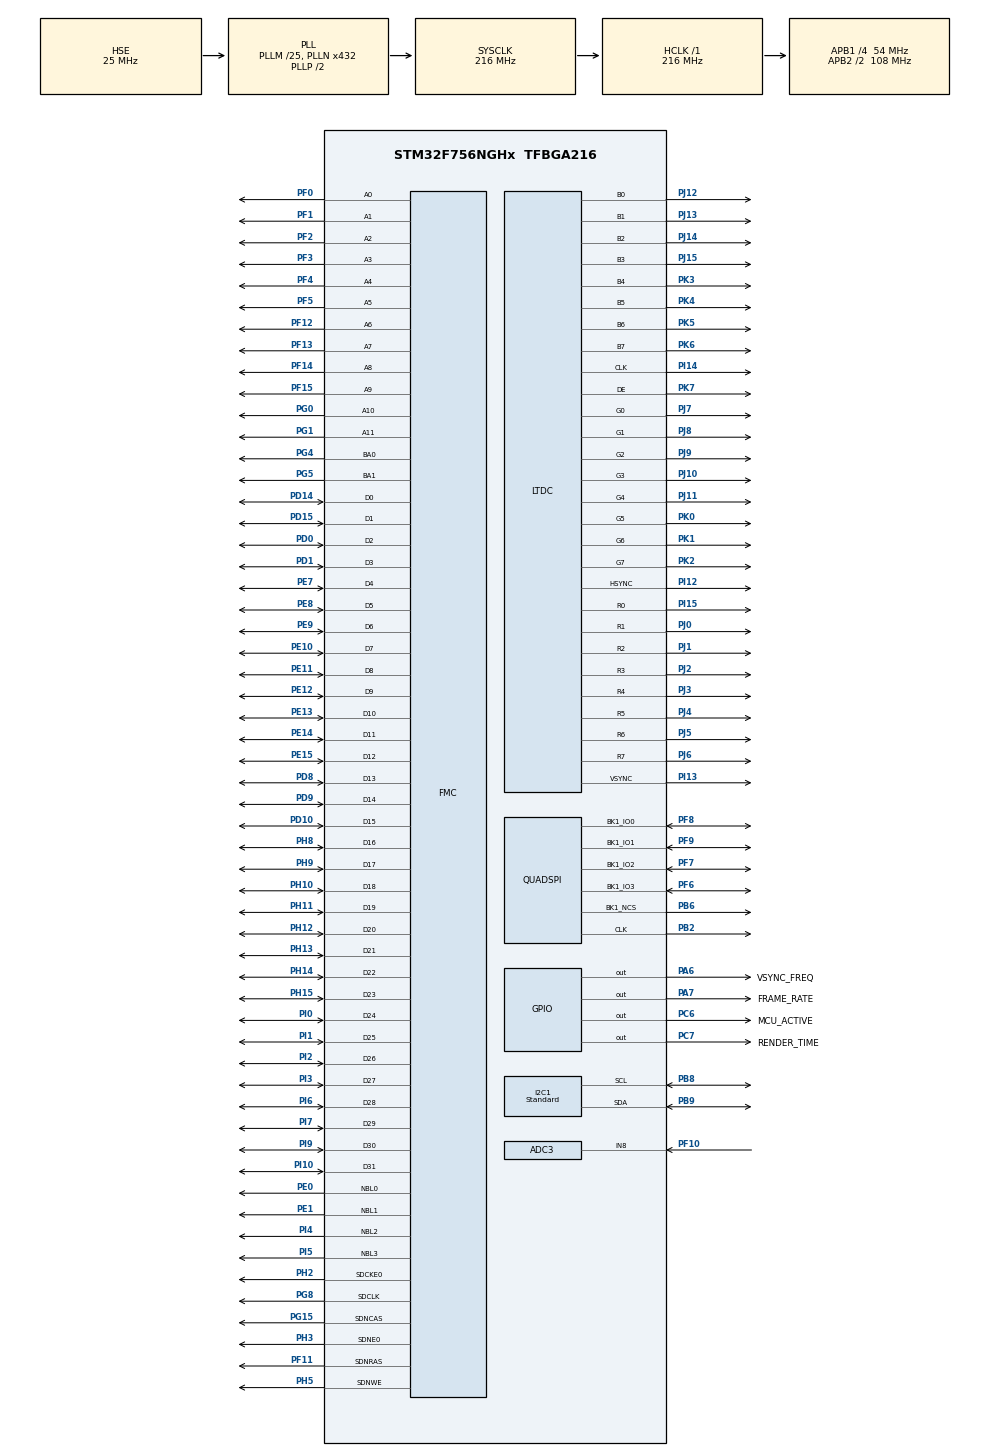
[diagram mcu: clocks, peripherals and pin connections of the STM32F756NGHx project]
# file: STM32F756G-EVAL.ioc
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ADC3.Channel-0\#ChannelRegularConversion=ADC_CHANNEL_8
ADC3.Channel-IN8=ADC_CHANNEL_8
ADC3.ClockPrescaler=ADC_CLOCK_SYNC_PCLK_DIV4
ADC3.ContinuousConvMode=DISABLE
ADC3.DMAContinuousRequests=DISABLE
ADC3.DataAlign=ADC_DATAALIGN_RIGHT
ADC3.DiscontinuousConvMode=DISABLE
ADC3.EOCSelection=ADC_EOC_SINGLE_CONV
ADC3.EnableAnalogWatchDog=false
ADC3.ExternalTrigConv=ADC_EXTERNALTRIGCONV_T1_CC1
ADC3.ExternalTrigConvEdge=ADC_EXTERNALTRIGCONVEDGE_RISING
ADC3.InjNumberOfConversion=0
ADC3.Mode=__NULL
ADC3.NbrOfConversion=1
ADC3.Rank-0\#ChannelRegularConversion=1
ADC3.Resolution=ADC_RESOLUTION_12B
ADC3.SamplingTime-0\#ChannelRegularConversion=ADC_SAMPLETIME_3CYCLES
ADC3.ScanConvMode=ADC_SCAN_DISABLE
CORTEX_M7.ART_ACCLERATOR_ENABLE=1
CORTEX_M7.AccessPermission-Cortex_Memory_Protection_Unit_Region0_Settings=MPU_REGION_NO_ACCESS
CORTEX_M7.AccessPermission-Cortex_Memory_Protection_Unit_Region1_Settings=MPU_REGION_FULL_ACCESS
CORTEX_M7.AccessPermission-Cortex_Memory_Protection_Unit_Region2_Settings=MPU_REGION_NO_ACCESS
CORTEX_M7.AccessPermission-Cortex_Memory_Protection_Unit_Region3_Settings=MPU_REGION_FULL_ACCESS
CORTEX_M7.BaseAddress-Cortex_Memory_Protection_Unit_Region0_Settings=0xC0000000
CORTEX_M7.BaseAddress-Cortex_Memory_Protection_Unit_Region1_Settings=0xC0000000
CORTEX_M7.BaseAddress-Cortex_Memory_Protection_Unit_Region2_Settings=0x90000000
CORTEX_M7.BaseAddress-Cortex_Memory_Protection_Unit_Region3_Settings=0x90000000
CORTEX_M7.CPU_DCache=Enabled
CORTEX_M7.CPU_ICache=Enabled
CORTEX_M7.DisableExec-Cortex_Memory_Protection_Unit_Region0_Settings=MPU_INSTRUCTION_ACCESS_DISABLE
CORTEX_M7.DisableExec-Cortex_Memory_Protection_Unit_Region1_Settings=MPU_INSTRUCTION_ACCESS_DISABLE
CORTEX_M7.DisableExec-Cortex_Memory_Protection_Unit_Region2_Settings=MPU_INSTRUCTION_ACCESS_DISABLE
CORTEX_M7.DisableExec-Cortex_Memory_Protection_Unit_Region3_Settings=MPU_INSTRUCTION_ACCESS_DISABLE
CORTEX_M7.Enable-Cortex_Memory_Protection_Unit_Region0_Settings=MPU_REGION_ENABLE
CORTEX_M7.Enable-Cortex_Memory_Protection_Unit_Region10_Settings=__NULL
CORTEX_M7.Enable-Cortex_Memory_Protection_Unit_Region11_Settings=__NULL
CORTEX_M7.Enable-Cortex_Memory_Protection_Unit_Region12_Settings=__NULL
CORTEX_M7.Enable-Cortex_Memory_Protection_Unit_Region13_Settings=__NULL
CORTEX_M7.Enable-Cortex_Memory_Protection_Unit_Region14_Settings=__NULL
CORTEX_M7.Enable-Cortex_Memory_Protection_Unit_Region15_Settings=__NULL
CORTEX_M7.Enable-Cortex_Memory_Protection_Unit_Region1_Settings=MPU_REGION_ENABLE
CORTEX_M7.Enable-Cortex_Memory_Protection_Unit_Region2_Settings=MPU_REGION_ENABLE
CORTEX_M7.Enable-Cortex_Memory_Protection_Unit_Region3_Settings=MPU_REGION_ENABLE
CORTEX_M7.Enable-Cortex_Memory_Protection_Unit_Region4_Settings=__NULL
CORTEX_M7.Enable-Cortex_Memory_Protection_Unit_Region5_Settings=__NULL
CORTEX_M7.Enable-Cortex_Memory_Protection_Unit_Region6_Settings=__NULL
CORTEX_M7.Enable-Cortex_Memory_Protection_Unit_Region7_Settings=__NULL
CORTEX_M7.Enable-Cortex_Memory_Protection_Unit_Region8_Settings=__NULL
CORTEX_M7.Enable-Cortex_Memory_Protection_Unit_Region9_Settings=__NULL
CORTEX_M7.FlashInterface=AXI_Enabled
CORTEX_M7.IsBufferable-Cortex_Memory_Protection_Unit_Region0_Settings=MPU_ACCESS_NOT_BUFFERABLE
CORTEX_M7.IsBufferable-Cortex_Memory_Protection_Unit_Region1_Settings=MPU_ACCESS_BUFFERABLE
CORTEX_M7.IsBufferable-Cortex_Memory_Protection_Unit_Region2_Settings=MPU_ACCESS_NOT_BUFFERABLE
CORTEX_M7.IsBufferable-Cortex_Memory_Protection_Unit_Region3_Settings=MPU_ACCESS_BUFFERABLE
CORTEX_M7.IsCacheable-Cortex_Memory_Protection_Unit_Region0_Settings=MPU_ACCESS_NOT_CACHEABLE
CORTEX_M7.IsCacheable-Cortex_Memory_Protection_Unit_Region1_Settings=MPU_ACCESS_CACHEABLE
CORTEX_M7.IsCacheable-Cortex_Memory_Protection_Unit_Region2_Settings=MPU_ACCESS_NOT_CACHEABLE
CORTEX_M7.IsCacheable-Cortex_Memory_Protection_Unit_Region3_Settings=MPU_ACCESS_CACHEABLE
CORTEX_M7.IsShareable-Cortex_Memory_Protection_Unit_Region0_Settings=MPU_ACCESS_NOT_SHAREABLE
CORTEX_M7.IsShareable-Cortex_Memory_Protection_Unit_Region1_Settings=MPU_ACCESS_NOT_SHAREABLE
CORTEX_M7.IsShareable-Cortex_Memory_Protection_Unit_Region2_Settings=MPU_ACCESS_NOT_SHAREABLE
CORTEX_M7.IsShareable-Cortex_Memory_Protection_Unit_Region3_Settings=MPU_ACCESS_NOT_SHAREABLE
CORTEX_M7.MPU_Control=MPU_PRIVILEGED_DEFAULT
CORTEX_M7.PREFETCH_ENABLE=1
CORTEX_M7.Size-Cortex_Memory_Protection_Unit_Region0_Settings=MPU_REGION_SIZE_512MB
CORTEX_M7.Size-Cortex_Memory_Protection_Unit_Region1_Settings=MPU_REGION_SIZE_8MB
CORTEX_M7.Size-Cortex_Memory_Protection_Unit_Region2_Settings=MPU_REGION_SIZE_512MB
CORTEX_M7.Size-Cortex_Memory_Protection_Unit_Region3_Settings=MPU_REGION_SIZE_64MB
CORTEX_M7.SubRegionDisable-Cortex_Memory_Protection_Unit_Region0_Settings=0x0
CORTEX_M7.SubRegionDisable-Cortex_Memory_Protection_Unit_Region1_Settings=0x0
CORTEX_M7.SubRegionDisable-Cortex_Memory_Protection_Unit_Region2_Settings=0x00
CORTEX_M7.SubRegionDisable-Cortex_Memory_Protection_Unit_Region3_Settings=0x0
CORTEX_M7.TypeExtField-Cortex_Memory_Protection_Unit_Region0_Settings=MPU_TEX_LEVEL0
CORTEX_M7.TypeExtField-Cortex_Memory_Protection_Unit_Region1_Settings=MPU_TEX_LEVEL0
CORTEX_M7.TypeExtField-Cortex_Memory_Protection_Unit_Region2_Settings=MPU_TEX_LEVEL0
CORTEX_M7.TypeExtField-Cortex_Memory_Protection_Unit_Region3_Settings=MPU_TEX_LEVEL0
CRC.DefaultInitValueUse=DEFAULT_INIT_VALUE_ENABLE
CRC.DefaultPolynomialUse=DEFAULT_POLYNOMIAL_ENABLE
CRC.InputDataFormat=CRC_INPUTDATA_FORMAT_WORDS
CRC.InputDataInversionMode=CRC_INPUTDATA_INVERSION_NONE
CRC.OutputDataInversionMode=CRC_OUTPUTDATA_INVERSION_DISABLE
DMA2D.ColorMode=DMA2D_OUTPUT_RGB565
DMA2D.Mode=DMA2D_R2M
DMA2D.OutputOffset=0
FMC.CASLatency1=FMC_SDRAM_CAS_LATENCY_3
FMC.ColumnBitsNumber1=FMC_SDRAM_COLUMN_BITS_NUM_9
FMC.ExitSelfRefreshDelay1=7
FMC.LoadToActiveDelay1=2
FMC.RCDDelay1=2
FMC.RPDelay1=2
FMC.ReadBurst1=FMC_SDRAM_RBURST_ENABLE
FMC.ReadPipeDelay1=FMC_SDRAM_RPIPE_DELAY_0
FMC.RowBitsNumber1=FMC_SDRAM_ROW_BITS_NUM_12
FMC.RowCycleDelay1=7
FMC.SDBank1=FMC_SDRAM_BANK1
FMC.SDClockPeriod1=FMC_SDRAM_CLOCK_PERIOD_2
FMC.SelfRefreshTime1=4
FMC.WriteProtection1=FMC_SDRAM_WRITE_PROTECTION_DISABLE
FMC.WriteRecoveryTime1=3
FREERTOS.HEAP_NUMBER=4
FREERTOS.INCLUDE_eTaskGetState=1
FREERTOS.INCLUDE_pcTaskGetTaskName=0
FREERTOS.INCLUDE_uxTaskGetStackHighWaterMark=1
FREERTOS.INCLUDE_uxTaskPriorityGet=1
FREERTOS.INCLUDE_vTaskCleanUpResources=0
FREERTOS.INCLUDE_vTaskDelay=1
FREERTOS.INCLUDE_vTaskDelayUntil=1
FREERTOS.INCLUDE_vTaskDelete=1
FREERTOS.INCLUDE_vTaskPrioritySet=1
FREERTOS.INCLUDE_vTaskSuspend=1
FREERTOS.INCLUDE_xEventGroupSetBitFromISR=0
FREERTOS.INCLUDE_xQueueGetMutexHolder=1
FREERTOS.INCLUDE_xSemaphoreGetMutexHolder=0
FREERTOS.INCLUDE_xTaskAbortDelay=0
FREERTOS.INCLUDE_xTaskGetCurrentTaskHandle=0
FREERTOS.INCLUDE_xTaskGetHandle=0
FREERTOS.INCLUDE_xTaskGetSchedulerState=1
FREERTOS.INCLUDE_xTaskResumeFromISR=1
FREERTOS.INCLUDE_xTimerPendFunctionCall=1
FREERTOS.Tasks01=defaultTask,24,128,StartDefaultTask,Default,NULL,Dynamic,NULL,NULL;TouchGFXTask,24,2048,TouchGFX_Task,As external,NULL,Dynamic,NULL,NULL
FREERTOS.configCHECK_FOR_STACK_OVERFLOW=0
FREERTOS.configENABLE_BACKWARD_COMPATIBILITY=1
FREERTOS.configGENERATE_RUN_TIME_STATS=0
FREERTOS.configIDLE_SHOULD_YIELD=1
FREERTOS.configLIBRARY_LOWEST_INTERRUPT_PRIORITY=15
FREERTOS.configLIBRARY_MAX_SYSCALL_INTERRUPT_PRIORITY=5
FREERTOS.configMAX_CO_ROUTINE_PRIORITIES=2
FREERTOS.configMAX_PRIORITIES=56
FREERTOS.configMAX_TASK_NAME_LEN=16
FREERTOS.configMINIMAL_STACK_SIZE=128
FREERTOS.configQUEUE_REGISTRY_SIZE=8
FREERTOS.configRECORD_STACK_HIGH_ADDRESS=0
FREERTOS.configTICK_RATE_HZ=1000
FREERTOS.configTIMER_QUEUE_LENGTH=10
FREERTOS.configTIMER_TASK_PRIORITY=2
FREERTOS.configTIMER_TASK_STACK_DEPTH=256
FREERTOS.configTOTAL_HEAP_SIZE=15360
FREERTOS.configUSE_APPLICATION_TASK_TAG=1
FREERTOS.configUSE_COUNTING_SEMAPHORES=1
FREERTOS.configUSE_CO_ROUTINES=0
FREERTOS.configUSE_DAEMON_TASK_STARTUP_HOOK=0
FREERTOS.configUSE_IDLE_HOOK=1
FREERTOS.configUSE_MALLOC_FAILED_HOOK=0
FREERTOS.configUSE_MUTEXES=1
FREERTOS.configUSE_PREEMPTION=1
FREERTOS.configUSE_RECURSIVE_MUTEXES=1
FREERTOS.configUSE_STATS_FORMATTING_FUNCTIONS=0
FREERTOS.configUSE_TASK_NOTIFICATIONS=1
FREERTOS.configUSE_TICKLESS_IDLE=0
FREERTOS.configUSE_TICK_HOOK=0
FREERTOS.configUSE_TRACE_FACILITY=1
I2C1.AddressingMode=I2C_ADDRESSINGMODE_7BIT
I2C1.Analog_Filter=I2C_ANALOGFILTER_ENABLE
I2C1.DualAddressMode=I2C_DUALADDRESS_DISABLE
I2C1.GeneralCallMode=I2C_GENERALCALL_DISABLE
I2C1.I2C_Coeff_DF=0
I2C1.I2C_Fall_Time=0
I2C1.I2C_Rise_Time=0
I2C1.I2C_Speed_Mode=I2C_Standard
I2C1.NoStretchMode=I2C_NOSTRETCH_DISABLE
I2C1.OwnAddress=0
I2C1.Speed=100
I2C1.Timing=0x20404768
LTDC.ActiveH=480
LTDC.ActiveW=640
LTDC.Alpha0_L0=0
LTDC.Alpha_L0=255
LTDC.BlendingFactor1_L0=LTDC_BLENDING_FACTOR1_CA
LTDC.BlendingFactor2_L0=LTDC_BLENDING_FACTOR2_CA
LTDC.Blue=0
LTDC.Blue_L0=0
LTDC.DEPolarity=LTDC_DEPOLARITY_AL
LTDC.FBStartAdress_L0=0xc0000000
LTDC.Green=0
LTDC.Green_L0=0
LTDC.HBP=114
LTDC.HFP=16
LTDC.HSPolarity=LTDC_HSPOLARITY_AL
LTDC.HSync=30
LTDC.ImageHeight_L0=480
LTDC.ImageWidth_L0=640
LTDC.Layers=0
LTDC.PCPolarity=LTDC_PCPOLARITY_IPC
LTDC.PixelFormat_L0=LTDC_PIXEL_FORMAT_RGB565
LTDC.Red=0
LTDC.Red_L0=0
LTDC.VBP=32
LTDC.VFP=10
LTDC.VSPolarity=LTDC_VSPOLARITY_AL
LTDC.VSync=3
LTDC.WindowX0_L0=0
LTDC.WindowX1_L0=640
LTDC.WindowY0_L0=0
LTDC.WindowY1_L0=480
Mcu.Family=STM32F7
Mcu.Name=STM32F756NGHx
Mcu.Package=TFBGA216
NVIC.DMA2D_IRQn=true\:5\:0\:true\:false\:true\:false\:true\:true\:true
NVIC.I2C1_EV_IRQn=true\:5\:0\:false\:false\:true\:false\:true\:true\:true
NVIC.LTDC_IRQn=true\:5\:0\:true\:false\:true\:false\:true\:true\:true
NVIC.PriorityGroup=NVIC_PRIORITYGROUP_4
NVIC.TIM6_DAC_IRQn=true\:0\:0\:false\:false\:true\:false\:false\:true\:true
NVIC.TimeBase=TIM6_DAC_IRQn
NVIC.TimeBaseIP=TIM6
PA13.Mode=Serial_Wire
PA13.Signal=SYS_JTMS-SWDIO
PA14.Mode=Serial_Wire
PA14.Signal=SYS_JTCK-SWCLK
PA6.GPIO_Label=VSYNC_FREQ
PA6.GPIO_Speed=GPIO_SPEED_FREQ_VERY_HIGH
PA6.Signal=GPIO_Output
PA7.GPIO_Label=FRAME_RATE
PA7.GPIO_Speed=GPIO_SPEED_FREQ_VERY_HIGH
PA7.Signal=GPIO_Output
PB2.Mode=Single Bank 1
PB2.Signal=QUADSPI_CLK
PB6.GPIO_PuPd=GPIO_PULLUP
PB6.Mode=Single Bank 1
PB6.Signal=QUADSPI_BK1_NCS
PB8.GPIO_Pu=GPIO_NOPULL
PB8.Mode=I2C
PB8.Signal=I2C1_SCL
PB9.GPIO_Pu=GPIO_NOPULL
PB9.Mode=I2C
PB9.Signal=I2C1_SDA
PC6.GPIO_Label=MCU_ACTIVE
PC6.GPIO_Speed=GPIO_SPEED_FREQ_VERY_HIGH
PC6.Signal=GPIO_Output
PC7.GPIO_Label=RENDER_TIME
PC7.GPIO_Speed=GPIO_SPEED_FREQ_VERY_HIGH
PC7.Signal=GPIO_Output
PD0.GPIO_PuPd=GPIO_PULLUP
PD0.Signal=FMC_D2_DA2
PD1.GPIO_PuPd=GPIO_PULLUP
PD1.Signal=FMC_D3_DA3
PD10.GPIO_PuPd=GPIO_PULLUP
PD10.Signal=FMC_D15_DA15
PD14.GPIO_PuPd=GPIO_PULLUP
PD14.Signal=FMC_D0_DA0
PD15.GPIO_PuPd=GPIO_PULLUP
PD15.Signal=FMC_D1_DA1
PD8.GPIO_PuPd=GPIO_PULLUP
PD8.Signal=FMC_D13_DA13
PD9.GPIO_PuPd=GPIO_PULLUP
PD9.Signal=FMC_D14_DA14
PE0.GPIO_PuPd=GPIO_PULLUP
PE0.Signal=FMC_NBL0
PE1.GPIO_PuPd=GPIO_PULLUP
PE1.Signal=FMC_NBL1
PE10.GPIO_PuPd=GPIO_PULLUP
PE10.Signal=FMC_D7_DA7
PE11.GPIO_PuPd=GPIO_PULLUP
PE11.Signal=FMC_D8_DA8
PE12.GPIO_PuPd=GPIO_PULLUP
PE12.Signal=FMC_D9_DA9
PE13.GPIO_PuPd=GPIO_PULLUP
PE13.Signal=FMC_D10_DA10
PE14.GPIO_PuPd=GPIO_PULLUP
PE14.Signal=FMC_D11_DA11
PE15.GPIO_PuPd=GPIO_PULLUP
PE15.Signal=FMC_D12_DA12
PE7.GPIO_PuPd=GPIO_PULLUP
PE7.Signal=FMC_D4_DA4
PE8.GPIO_PuPd=GPIO_PULLUP
PE8.Signal=FMC_D5_DA5
PE9.GPIO_PuPd=GPIO_PULLUP
PE9.Signal=FMC_D6_DA6
PF0.GPIO_PuPd=GPIO_PULLUP
PF0.Signal=FMC_A0
PF1.GPIO_PuPd=GPIO_PULLUP
PF1.Signal=FMC_A1
PF10.Mode=IN8
PF10.Signal=ADC3_IN8
PF11.GPIO_PuPd=GPIO_PULLUP
PF11.Signal=FMC_SDNRAS
PF12.GPIO_PuPd=GPIO_PULLUP
PF12.Signal=FMC_A6
PF13.GPIO_PuPd=GPIO_PULLUP
PF13.Signal=FMC_A7
PF14.GPIO_PuPd=GPIO_PULLUP
PF14.Signal=FMC_A8
PF15.GPIO_PuPd=GPIO_PULLUP
PF15.Signal=FMC_A9
PF2.GPIO_PuPd=GPIO_PULLUP
PF2.Signal=FMC_A2
PF3.GPIO_PuPd=GPIO_PULLUP
PF3.Signal=FMC_A3
PF4.GPIO_PuPd=GPIO_PULLUP
PF4.Signal=FMC_A4
PF5.GPIO_PuPd=GPIO_PULLUP
PF5.Signal=FMC_A5
PF6.Mode=Single Bank 1
PF6.Signal=QUADSPI_BK1_IO3
PF7.Mode=Single Bank 1
PF7.Signal=QUADSPI_BK1_IO2
PF8.Mode=Single Bank 1
PF8.Signal=QUADSPI_BK1_IO0
PF9.Mode=Single Bank 1
PF9.Signal=QUADSPI_BK1_IO1
PG0.GPIO_PuPd=GPIO_PULLUP
PG0.Signal=FMC_A10
PG1.GPIO_PuPd=GPIO_PULLUP
PG1.Signal=FMC_A11
PG15.GPIO_PuPd=GPIO_PULLUP
PG15.Signal=FMC_SDNCAS
PG4.GPIO_PuPd=GPIO_PULLUP
PG4.Signal=FMC_A14_BA0
PG5.GPIO_PuPd=GPIO_PULLUP
PG5.Signal=FMC_A15_BA1
PG8.GPIO_PuPd=GPIO_PULLUP
PG8.Signal=FMC_SDCLK
PH0/OSC_IN.Mode=HSE-External-Oscillator
PH0/OSC_IN.Signal=RCC_OSC_IN
PH1/OSC_OUT.Mode=HSE-External-Oscillator
PH1/OSC_OUT.Signal=RCC_OSC_OUT
PH10.GPIO_PuPd=GPIO_PULLUP
PH10.Signal=FMC_D18
PH11.GPIO_PuPd=GPIO_PULLUP
PH11.Signal=FMC_D19
PH12.GPIO_PuPd=GPIO_PULLUP
PH12.Signal=FMC_D20
PH13.GPIO_PuPd=GPIO_PULLUP
PH13.Signal=FMC_D21
PH14.GPIO_PuPd=GPIO_PULLUP
PH14.Signal=FMC_D22
PH15.GPIO_PuPd=GPIO_PULLUP
PH15.Signal=FMC_D23
PH2.GPIO_PuPd=GPIO_PULLUP
PH2.Mode=SdramChipSelect1_1
PH2.Signal=FMC_SDCKE0
PH3.GPIO_PuPd=GPIO_PULLUP
PH3.Mode=SdramChipSelect1_1
PH3.Signal=FMC_SDNE0
PH5.GPIO_PuPd=GPIO_PULLUP
PH5.Signal=FMC_SDNWE
PH8.GPIO_PuPd=GPIO_PULLUP
PH8.Signal=FMC_D16
PH9.GPIO_PuPd=GPIO_PULLUP
PH9.Signal=FMC_D17
PI0.GPIO_PuPd=GPIO_PULLUP
PI0.Signal=FMC_D24
PI1.GPIO_PuPd=GPIO_PULLUP
PI1.Signal=FMC_D25
PI10.GPIO_PuPd=GPIO_PULLUP
PI10.Signal=FMC_D31
PI12.GPIO_Speed=GPIO_SPEED_FREQ_HIGH
PI12.Mode=RGB888
PI12.Signal=LTDC_HSYNC
PI13.GPIO_Speed=GPIO_SPEED_FREQ_HIGH
PI13.Mode=RGB888
PI13.Signal=LTDC_VSYNC
PI14.GPIO_Speed=GPIO_SPEED_FREQ_HIGH
PI14.Mode=RGB888
PI14.Signal=LTDC_CLK
PI15.GPIO_Speed=GPIO_SPEED_FREQ_HIGH
PI15.Mode=RGB888
PI15.Signal=LTDC_R0
PI2.GPIO_PuPd=GPIO_PULLUP
PI2.Signal=FMC_D26
PI3.GPIO_PuPd=GPIO_PULLUP
PI3.Signal=FMC_D27
PI4.GPIO_PuPd=GPIO_PULLUP
PI4.Signal=FMC_NBL2
PI5.GPIO_PuPd=GPIO_PULLUP
PI5.Signal=FMC_NBL3
PI6.GPIO_PuPd=GPIO_PULLUP
PI6.Signal=FMC_D28
PI7.GPIO_PuPd=GPIO_PULLUP
PI7.Signal=FMC_D29
PI9.GPIO_PuPd=GPIO_PULLUP
PI9.Signal=FMC_D30
PJ0.GPIO_Speed=GPIO_SPEED_FREQ_HIGH
PJ0.Mode=RGB888
PJ0.Signal=LTDC_R1
PJ1.GPIO_Speed=GPIO_SPEED_FREQ_HIGH
PJ1.Mode=RGB888
PJ1.Signal=LTDC_R2
PJ10.GPIO_Speed=GPIO_SPEED_FREQ_HIGH
PJ10.Mode=RGB888
PJ10.Signal=LTDC_G3
PJ11.GPIO_Speed=GPIO_SPEED_FREQ_HIGH
PJ11.Mode=RGB888
PJ11.Signal=LTDC_G4
PJ12.GPIO_Speed=GPIO_SPEED_FREQ_HIGH
PJ12.Mode=RGB888
PJ12.Signal=LTDC_B0
PJ13.GPIO_Speed=GPIO_SPEED_FREQ_HIGH
PJ13.Mode=RGB888
PJ13.Signal=LTDC_B1
PJ14.GPIO_Speed=GPIO_SPEED_FREQ_HIGH
PJ14.Mode=RGB888
PJ14.Signal=LTDC_B2
PJ15.GPIO_Speed=GPIO_SPEED_FREQ_HIGH
PJ15.Mode=RGB888
PJ15.Signal=LTDC_B3
PJ2.GPIO_Speed=GPIO_SPEED_FREQ_HIGH
PJ2.Mode=RGB888
PJ2.Signal=LTDC_R3
PJ3.GPIO_Speed=GPIO_SPEED_FREQ_HIGH
PJ3.Mode=RGB888
PJ3.Signal=LTDC_R4
PJ4.GPIO_Speed=GPIO_SPEED_FREQ_HIGH
PJ4.Mode=RGB888
PJ4.Signal=LTDC_R5
PJ5.GPIO_Speed=GPIO_SPEED_FREQ_HIGH
PJ5.Mode=RGB888
PJ5.Signal=LTDC_R6
PJ6.GPIO_Speed=GPIO_SPEED_FREQ_HIGH
PJ6.Mode=RGB888
PJ6.Signal=LTDC_R7
PJ7.GPIO_Speed=GPIO_SPEED_FREQ_HIGH
PJ7.Mode=RGB888
PJ7.Signal=LTDC_G0
PJ8.GPIO_Speed=GPIO_SPEED_FREQ_HIGH
PJ8.Mode=RGB888
PJ8.Signal=LTDC_G1
PJ9.GPIO_Speed=GPIO_SPEED_FREQ_HIGH
PJ9.Mode=RGB888
PJ9.Signal=LTDC_G2
PK0.GPIO_Speed=GPIO_SPEED_FREQ_HIGH
PK0.Mode=RGB888
PK0.Signal=LTDC_G5
PK1.GPIO_Speed=GPIO_SPEED_FREQ_HIGH
PK1.Mode=RGB888
PK1.Signal=LTDC_G6
PK2.GPIO_Speed=GPIO_SPEED_FREQ_HIGH
PK2.Mode=RGB888
PK2.Signal=LTDC_G7
PK3.GPIO_Speed=GPIO_SPEED_FREQ_HIGH
PK3.Mode=RGB888
PK3.Signal=LTDC_B4
PK4.GPIO_Speed=GPIO_SPEED_FREQ_HIGH
PK4.Mode=RGB888
PK4.Signal=LTDC_B5
PK5.GPIO_Speed=GPIO_SPEED_FREQ_HIGH
PK5.Mode=RGB888
PK5.Signal=LTDC_B6
PK6.GPIO_Speed=GPIO_SPEED_FREQ_HIGH
PK6.Mode=RGB888
PK6.Signal=LTDC_B7
PK7.GPIO_Speed=GPIO_SPEED_FREQ_HIGH
PK7.Mode=RGB888
PK7.Signal=LTDC_DE
ProjectManager.HeapSize=0x1000
ProjectManager.StackSize=0x1000
ProjectManager.TargetToolchain=STM32CubeIDE
QUADSPI.ChipSelectHighTime=QSPI_CS_HIGH_TIME_6_CYCLE
QUADSPI.ClockMode=QSPI_CLOCK_MODE_0
QUADSPI.ClockPrescaler=1
QUADSPI.DualFlash=QSPI_DUALFLASH_DISABLE
QUADSPI.FifoThreshold=4
QUADSPI.FlashID=QSPI_FLASH_ID_1
QUADSPI.FlashSize=25
QUADSPI.SampleShifting=QSPI_SAMPLE_SHIFTING_HALFCYCLE
RCC.AHBFreq_Value=216000000
RCC.APB1CLKDivider=RCC_HCLK_DIV4
RCC.APB1Freq_Value=54000000
RCC.APB1TimFreq_Value=108000000
RCC.APB2CLKDivider=RCC_HCLK_DIV2
RCC.APB2Freq_Value=108000000
RCC.APB2TimFreq_Value=216000000
RCC.CortexFreq_Value=216000000
RCC.FLatency=FLASH_LATENCY_7
RCC.HCLKFreq_Value=216000000
RCC.HSE_VALUE=25000000
RCC.HSI_VALUE=16000000
RCC.LSE_VALUE=32768
RCC.PLLM=25
RCC.PLLN=432
RCC.PLLSAIN=100
RCC.PLLSourceVirtual=RCC_PLLSOURCE_HSE
RCC.PWREXT_OverDrive=PWREXT_OverDrive_ACTIVATED
RCC.PWR_Regulator_Voltage_Scale=PWR_REGULATOR_VOLTAGE_SCALE1
RCC.SYSCLKFreq_VALUE=216000000
RCC.SYSCLKSource=RCC_SYSCLKSOURCE_PLLCLK
RCC.USBFreq_Value=216000000
RCC.VCOOutputFreq_Value=432000000
SH.FMC_A0.0=FMC_A0,12b-sda1
SH.FMC_A1.0=FMC_A1,12b-sda1
SH.FMC_A10.0=FMC_A10,12b-sda1
SH.FMC_A11.0=FMC_A11,12b-sda1
SH.FMC_A14_BA0.0=FMC_BA0,FourSdramBanks1
SH.FMC_A15_BA1.0=FMC_BA1,FourSdramBanks1
SH.FMC_A2.0=FMC_A2,12b-sda1
SH.FMC_A3.0=FMC_A3,12b-sda1
SH.FMC_A4.0=FMC_A4,12b-sda1
SH.FMC_A5.0=FMC_A5,12b-sda1
SH.FMC_A6.0=FMC_A6,12b-sda1
SH.FMC_A7.0=FMC_A7,12b-sda1
SH.FMC_A8.0=FMC_A8,12b-sda1
SH.FMC_A9.0=FMC_A9,12b-sda1
SH.FMC_D0_DA0.0=FMC_D0,sd-32b-d1
SH.FMC_D10_DA10.0=FMC_D10,sd-32b-d1
SH.FMC_D11_DA11.0=FMC_D11,sd-32b-d1
SH.FMC_D12_DA12.0=FMC_D12,sd-32b-d1
SH.FMC_D13_DA13.0=FMC_D13,sd-32b-d1
SH.FMC_D14_DA14.0=FMC_D14,sd-32b-d1
SH.FMC_D15_DA15.0=FMC_D15,sd-32b-d1
SH.FMC_D16.0=FMC_D16,sd-32b-d1
SH.FMC_D17.0=FMC_D17,sd-32b-d1
SH.FMC_D18.0=FMC_D18,sd-32b-d1
SH.FMC_D19.0=FMC_D19,sd-32b-d1
SH.FMC_D1_DA1.0=FMC_D1,sd-32b-d1
SH.FMC_D20.0=FMC_D20,sd-32b-d1
SH.FMC_D21.0=FMC_D21,sd-32b-d1
SH.FMC_D22.0=FMC_D22,sd-32b-d1
SH.FMC_D23.0=FMC_D23,sd-32b-d1
SH.FMC_D24.0=FMC_D24,sd-32b-d1
SH.FMC_D25.0=FMC_D25,sd-32b-d1
SH.FMC_D26.0=FMC_D26,sd-32b-d1
SH.FMC_D27.0=FMC_D27,sd-32b-d1
SH.FMC_D28.0=FMC_D28,sd-32b-d1
SH.FMC_D29.0=FMC_D29,sd-32b-d1
SH.FMC_D2_DA2.0=FMC_D2,sd-32b-d1
SH.FMC_D30.0=FMC_D30,sd-32b-d1
SH.FMC_D31.0=FMC_D31,sd-32b-d1
SH.FMC_D3_DA3.0=FMC_D3,sd-32b-d1
SH.FMC_D4_DA4.0=FMC_D4,sd-32b-d1
SH.FMC_D5_DA5.0=FMC_D5,sd-32b-d1
SH.FMC_D6_DA6.0=FMC_D6,sd-32b-d1
SH.FMC_D7_DA7.0=FMC_D7,sd-32b-d1
SH.FMC_D8_DA8.0=FMC_D8,sd-32b-d1
SH.FMC_D9_DA9.0=FMC_D9,sd-32b-d1
SH.FMC_NBL0.0=FMC_NBL0,Sd4ByteEnable1
SH.FMC_NBL1.0=FMC_NBL1,Sd4ByteEnable1
SH.FMC_NBL2.0=FMC_NBL2,Sd4ByteEnable1
SH.FMC_NBL3.0=FMC_NBL3,Sd4ByteEnable1
SH.FMC_SDCLK.0=FMC_SDCLK,12b-sda1
SH.FMC_SDNCAS.0=FMC_SDNCAS,12b-sda1
SH.FMC_SDNRAS.0=FMC_SDNRAS,12b-sda1
SH.FMC_SDNWE.0=FMC_SDNWE,12b-sda1
STMicroelectronics.X-CUBE-TOUCHGFX.4.22.0.ApplicationCcGraphicsJjApplication=TouchGFXOoGenerator
STMicroelectronics.X-CUBE-TOUCHGFX.4.22.0.tgfx_address1=0xC0000000
STMicroelectronics.X-CUBE-TOUCHGFX.4.22.0.tgfx_address2=0xC0096000
STMicroelectronics.X-CUBE-TOUCHGFX.4.22.0.tgfx_buffering_strategy=Double
STMicroelectronics.X-CUBE-TOUCHGFX.4.22.0.tgfx_display_interface=disp_ltdc
STMicroelectronics.X-CUBE-TOUCHGFX.4.22.0.tgfx_hardware_accelerator=dma_2d
STMicroelectronics.X-CUBE-TOUCHGFX.4.22.0.tgfx_location=By Address
STMicroelectronics.X-CUBE-TOUCHGFX.4.22.0.tgfx_vector_rendering=Enabled
STMicroelectronics.X-CUBE-TOUCHGFX.4.22.0.tgfx_vsync=vsync_ltdc
VP_CRC_VS_CRC.Mode=CRC_Activate
VP_DMA2D_VS_DMA2D.Mode=DMA2D_Activate
VP_FREERTOS_VS_CMSIS_V2.Mode=CMSIS_V2
VP_STMicroelectronics.X-CUBE-TOUCHGFX_VS_GraphicsJjApplication_4.22.0.Mode=GraphicsJjApplication
VP_SYS_VS_tim6.Mode=TIM6
board=custom

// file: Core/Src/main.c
/* USER CODE BEGIN Header */
/**
  ******************************************************************************
  * @file           : main.c
  * @brief          : Main program body
  ******************************************************************************
  * @attention
  *
  * <h2><center>&copy; Copyright (c) 2020 STMicroelectronics.
  * All rights reserved.</center></h2>
  *
  * This software component is licensed by ST under BSD 3-Clause license,
  * the "License"; You may not use this file except in compliance with the
  * License. You may obtain a copy of the License at:
  *                        opensource.org/licenses/BSD-3-Clause
  *
  ******************************************************************************
  */
/* USER CODE END Header */
#include "main.h"
#include "cmsis_os.h"
#include "app_touchgfx.h"

/* USER CODE BEGIN Includes */
#include "../n25q512a/n25q512a.h"
#include "../ft5336/ft5336.h"

/* USER CODE END Includes */

/* USER CODE BEGIN PD */
/* QSPI Error codes */
#define QSPI_OK            ((uint8_t)0x00)
#define QSPI_ERROR         ((uint8_t)0x01)
#define QSPI_BUSY          ((uint8_t)0x02)
#define QSPI_NOT_SUPPORTED ((uint8_t)0x04)
#define QSPI_SUSPENDED     ((uint8_t)0x08)
// SDRAM
#define REFRESH_COUNT                    ((uint32_t)0x0603)   /* SDRAM refresh counter (100Mhz SD clock) */
#define SDRAM_TIMEOUT                    ((uint32_t)0xFFFF)
//  FMC SDRAM Mode definition register defines
#define SDRAM_MODEREG_BURST_LENGTH_1             ((uint16_t)0x0000)
#define SDRAM_MODEREG_BURST_LENGTH_2             ((uint16_t)0x0001)
#define SDRAM_MODEREG_BURST_LENGTH_4             ((uint16_t)0x0002)
#define SDRAM_MODEREG_BURST_LENGTH_8             ((uint16_t)0x0004)
#define SDRAM_MODEREG_BURST_TYPE_SEQUENTIAL      ((uint16_t)0x0000)
#define SDRAM_MODEREG_BURST_TYPE_INTERLEAVED     ((uint16_t)0x0008)
#define SDRAM_MODEREG_CAS_LATENCY_2              ((uint16_t)0x0020)
#define SDRAM_MODEREG_CAS_LATENCY_3              ((uint16_t)0x0030)
#define SDRAM_MODEREG_OPERATING_MODE_STANDARD    ((uint16_t)0x0000)
#define SDRAM_MODEREG_WRITEBURST_MODE_PROGRAMMED ((uint16_t)0x0000)
#define SDRAM_MODEREG_WRITEBURST_MODE_SINGLE     ((uint16_t)0x0200)

/* USER CODE END PD */

ADC_HandleTypeDef hadc3;

CRC_HandleTypeDef hcrc;

DMA2D_HandleTypeDef hdma2d;

I2C_HandleTypeDef hi2c1;

LTDC_HandleTypeDef hltdc;

QSPI_HandleTypeDef hqspi;

SDRAM_HandleTypeDef hsdram1;

/* Definitions for defaultTask */
osThreadId_t defaultTaskHandle;
const osThreadAttr_t defaultTask_attributes = {
  .name = "defaultTask",
  .stack_size = 128 * 4,
  .priority = (osPriority_t) osPriorityNormal,
};
/* Definitions for TouchGFXTask */
osThreadId_t TouchGFXTaskHandle;
const osThreadAttr_t TouchGFXTask_attributes = {
  .name = "TouchGFXTask",
  .stack_size = 2048 * 4,
  .priority = (osPriority_t) osPriorityNormal,
};

void SystemClock_Config(void);
static void MPU_Initialize(void);
static void MPU_Config(void);
static void MX_GPIO_Init(void);
static void MX_QUADSPI_Init(void);
static void MX_FMC_Init(void);
static void MX_LTDC_Init(void);
static void MX_CRC_Init(void);
static void MX_DMA2D_Init(void);
static void MX_ADC3_Init(void);
static void MX_I2C1_Init(void);
void StartDefaultTask(void *argument);
extern void TouchGFX_Task(void *argument);

/* USER CODE BEGIN PFP */
static uint8_t QSPI_ResetMemory          (QSPI_HandleTypeDef *hqspi);
static uint8_t QSPI_EnterFourBytesAddress(QSPI_HandleTypeDef *hqspi);
static uint8_t QSPI_DummyCyclesCfg       (QSPI_HandleTypeDef *hqspi);
static uint8_t QSPI_WriteEnable          (QSPI_HandleTypeDef *hqspi);
static uint8_t QSPI_AutoPollingMemReady(QSPI_HandleTypeDef *hqspi, uint32_t Timeout);
static uint8_t QSPI_EnableMemoryMappedMode(void);

static FMC_SDRAM_CommandTypeDef Command;
void    BSP_SDRAM_Initialization_sequence(uint32_t RefreshCount);

/* USER CODE END PFP */

int main(void)
{

  /* Enable I-Cache---------------------------------------------------------*/
  SCB_EnableICache();

  /* Enable D-Cache---------------------------------------------------------*/
  SCB_EnableDCache();

  /* MCU Configuration--------------------------------------------------------*/

  /* Reset of all peripherals, Initializes the Flash interface and the Systick. */
  HAL_Init();

  /* MPU Configuration--------------------------------------------------------*/
  MPU_Config();

  /* Configure the system clock */
  SystemClock_Config();

  /* Initialize all configured peripherals */
  MX_GPIO_Init();
  MX_QUADSPI_Init();
  MX_FMC_Init();
  MX_LTDC_Init();
  MX_CRC_Init();
  MX_DMA2D_Init();
  MX_ADC3_Init();
  MX_I2C1_Init();
  MX_TouchGFX_Init();
  /* Call PreOsInit function */
  MX_TouchGFX_PreOSInit();

  /* Init scheduler */
  osKernelInitialize();

  /* Create the thread(s) */
  /* creation of defaultTask */
  defaultTaskHandle = osThreadNew(StartDefaultTask, NULL, &defaultTask_attributes);

  /* creation of TouchGFXTask */
  TouchGFXTaskHandle = osThreadNew(TouchGFX_Task, NULL, &TouchGFXTask_attributes);

  /* Start scheduler */
  osKernelStart();

  /* We should never get here as control is now taken by the scheduler */
  /* Infinite loop */
  while (1)
  {

  }
}

void SystemClock_Config(void)
{
  RCC_OscInitTypeDef RCC_OscInitStruct = {0};
  RCC_ClkInitTypeDef RCC_ClkInitStruct = {0};

  /** Configure the main internal regulator output voltage
  */
  __HAL_RCC_PWR_CLK_ENABLE();
  __HAL_PWR_VOLTAGESCALING_CONFIG(PWR_REGULATOR_VOLTAGE_SCALE1);

  /** Initializes the RCC Oscillators according to the specified parameters
  * in the RCC_OscInitTypeDef structure.
  */
  RCC_OscInitStruct.OscillatorType = RCC_OSCILLATORTYPE_HSE;
  RCC_OscInitStruct.HSEState = RCC_HSE_ON;
  RCC_OscInitStruct.PLL.PLLState = RCC_PLL_ON;
  RCC_OscInitStruct.PLL.PLLSource = RCC_PLLSOURCE_HSE;
  RCC_OscInitStruct.PLL.PLLM = 25;
  RCC_OscInitStruct.PLL.PLLN = 432;
  RCC_OscInitStruct.PLL.PLLP = RCC_PLLP_DIV2;
  RCC_OscInitStruct.PLL.PLLQ = 2;
  if (HAL_RCC_OscConfig(&RCC_OscInitStruct) != HAL_OK)
  {
    Error_Handler();
  }

  /** Activate the Over-Drive mode
  */
  if (HAL_PWREx_EnableOverDrive() != HAL_OK)
  {
    Error_Handler();
  }

  /** Initializes the CPU, AHB and APB buses clocks
  */
  RCC_ClkInitStruct.ClockType = RCC_CLOCKTYPE_HCLK|RCC_CLOCKTYPE_SYSCLK
                              |RCC_CLOCKTYPE_PCLK1|RCC_CLOCKTYPE_PCLK2;
  RCC_ClkInitStruct.SYSCLKSource = RCC_SYSCLKSOURCE_PLLCLK;
  RCC_ClkInitStruct.AHBCLKDivider = RCC_SYSCLK_DIV1;
  RCC_ClkInitStruct.APB1CLKDivider = RCC_HCLK_DIV4;
  RCC_ClkInitStruct.APB2CLKDivider = RCC_HCLK_DIV2;

  if (HAL_RCC_ClockConfig(&RCC_ClkInitStruct, FLASH_LATENCY_7) != HAL_OK)
  {
    Error_Handler();
  }
}

static void MX_ADC3_Init(void)
{

  ADC_ChannelConfTypeDef sConfig = {0};

  /** Configure the global features of the ADC (Clock, Resolution, Data Alignment and number of conversion)
  */
  hadc3.Instance = ADC3;
  hadc3.Init.ClockPrescaler = ADC_CLOCK_SYNC_PCLK_DIV4;
  hadc3.Init.Resolution = ADC_RESOLUTION_12B;
  hadc3.Init.ScanConvMode = ADC_SCAN_DISABLE;
  hadc3.Init.ContinuousConvMode = DISABLE;
  hadc3.Init.DiscontinuousConvMode = DISABLE;
  hadc3.Init.ExternalTrigConvEdge = ADC_EXTERNALTRIGCONVEDGE_RISING;
  hadc3.Init.ExternalTrigConv = ADC_EXTERNALTRIGCONV_T1_CC1;
  hadc3.Init.DataAlign = ADC_DATAALIGN_RIGHT;
  hadc3.Init.NbrOfConversion = 1;
  hadc3.Init.DMAContinuousRequests = DISABLE;
  hadc3.Init.EOCSelection = ADC_EOC_SINGLE_CONV;
  if (HAL_ADC_Init(&hadc3) != HAL_OK)
  {
    Error_Handler();
  }

  /** Configure for the selected ADC regular channel its corresponding rank in the sequencer and its sample time.
  */
  sConfig.Channel = ADC_CHANNEL_8;
  sConfig.Rank = ADC_REGULAR_RANK_1;
  sConfig.SamplingTime = ADC_SAMPLETIME_3CYCLES;
  if (HAL_ADC_ConfigChannel(&hadc3, &sConfig) != HAL_OK)
  {
    Error_Handler();
  }

}

static void MX_CRC_Init(void)
{

  hcrc.Instance = CRC;
  hcrc.Init.DefaultPolynomialUse = DEFAULT_POLYNOMIAL_ENABLE;
  hcrc.Init.DefaultInitValueUse = DEFAULT_INIT_VALUE_ENABLE;
  hcrc.Init.InputDataInversionMode = CRC_INPUTDATA_INVERSION_NONE;
  hcrc.Init.OutputDataInversionMode = CRC_OUTPUTDATA_INVERSION_DISABLE;
  hcrc.InputDataFormat = CRC_INPUTDATA_FORMAT_WORDS;
  if (HAL_CRC_Init(&hcrc) != HAL_OK)
  {
    Error_Handler();
  }

}

static void MX_DMA2D_Init(void)
{

  hdma2d.Instance = DMA2D;
  hdma2d.Init.Mode = DMA2D_R2M;
  hdma2d.Init.ColorMode = DMA2D_OUTPUT_RGB565;
  hdma2d.Init.OutputOffset = 0;
  if (HAL_DMA2D_Init(&hdma2d) != HAL_OK)
  {
    Error_Handler();
  }

}

static void MX_I2C1_Init(void)
{

  hi2c1.Instance = I2C1;
  hi2c1.Init.Timing = 0x20404768;
  hi2c1.Init.OwnAddress1 = 0;
  hi2c1.Init.AddressingMode = I2C_ADDRESSINGMODE_7BIT;
  hi2c1.Init.DualAddressMode = I2C_DUALADDRESS_DISABLE;
  hi2c1.Init.OwnAddress2 = 0;
  hi2c1.Init.OwnAddress2Masks = I2C_OA2_NOMASK;
  hi2c1.Init.GeneralCallMode = I2C_GENERALCALL_DISABLE;
  hi2c1.Init.NoStretchMode = I2C_NOSTRETCH_DISABLE;
  if (HAL_I2C_Init(&hi2c1) != HAL_OK)
  {
    Error_Handler();
  }

  /** Configure Analogue filter
  */
  if (HAL_I2CEx_ConfigAnalogFilter(&hi2c1, I2C_ANALOGFILTER_ENABLE) != HAL_OK)
  {
    Error_Handler();
  }

  /** Configure Digital filter
  */
  if (HAL_I2CEx_ConfigDigitalFilter(&hi2c1, 0) != HAL_OK)
  {
    Error_Handler();
  }

}

static void MX_LTDC_Init(void)
{

  LTDC_LayerCfgTypeDef pLayerCfg = {0};

  hltdc.Instance = LTDC;
  hltdc.Init.HSPolarity = LTDC_HSPOLARITY_AL;
  hltdc.Init.VSPolarity = LTDC_VSPOLARITY_AL;
  hltdc.Init.DEPolarity = LTDC_DEPOLARITY_AL;
  hltdc.Init.PCPolarity = LTDC_PCPOLARITY_IPC;
  hltdc.Init.HorizontalSync = 29;
  hltdc.Init.VerticalSync = 2;
  hltdc.Init.AccumulatedHBP = 143;
  hltdc.Init.AccumulatedVBP = 34;
  hltdc.Init.AccumulatedActiveW = 783;
  hltdc.Init.AccumulatedActiveH = 514;
  hltdc.Init.TotalWidth = 799;
  hltdc.Init.TotalHeigh = 524;
  hltdc.Init.Backcolor.Blue = 0;
  hltdc.Init.Backcolor.Green = 0;
  hltdc.Init.Backcolor.Red = 0;
  if (HAL_LTDC_Init(&hltdc) != HAL_OK)
  {
    Error_Handler();
  }
  pLayerCfg.WindowX0 = 0;
  pLayerCfg.WindowX1 = 640;
  pLayerCfg.WindowY0 = 0;
  pLayerCfg.WindowY1 = 480;
  pLayerCfg.PixelFormat = LTDC_PIXEL_FORMAT_RGB565;
  pLayerCfg.Alpha = 255;
  pLayerCfg.Alpha0 = 0;
  pLayerCfg.BlendingFactor1 = LTDC_BLENDING_FACTOR1_CA;
  pLayerCfg.BlendingFactor2 = LTDC_BLENDING_FACTOR2_CA;
  pLayerCfg.FBStartAdress = 0xc0000000;
  pLayerCfg.ImageWidth = 640;
  pLayerCfg.ImageHeight = 480;
  pLayerCfg.Backcolor.Blue = 0;
  pLayerCfg.Backcolor.Green = 0;
  pLayerCfg.Backcolor.Red = 0;
  if (HAL_LTDC_ConfigLayer(&hltdc, &pLayerCfg, 0) != HAL_OK)
  {
    Error_Handler();
  }

}

static void MX_QUADSPI_Init(void)
{

  /* USER CODE BEGIN QUADSPI_Init 1 */
  if (HAL_QSPI_DeInit(&hqspi) != HAL_OK)
  {
    Error_Handler();
  }
  /* USER CODE END QUADSPI_Init 1 */
  /* QUADSPI parameter configuration*/
  hqspi.Instance = QUADSPI;
  hqspi.Init.ClockPrescaler = 1;
  hqspi.Init.FifoThreshold = 4;
  hqspi.Init.SampleShifting = QSPI_SAMPLE_SHIFTING_HALFCYCLE;
  hqspi.Init.FlashSize = 25;
  hqspi.Init.ChipSelectHighTime = QSPI_CS_HIGH_TIME_6_CYCLE;
  hqspi.Init.ClockMode = QSPI_CLOCK_MODE_0;
  hqspi.Init.FlashID = QSPI_FLASH_ID_1;
  hqspi.Init.DualFlash = QSPI_DUALFLASH_DISABLE;
  if (HAL_QSPI_Init(&hqspi) != HAL_OK)
  {
    Error_Handler();
  }
  /* USER CODE BEGIN QUADSPI_Init 2 */
  /* QSPI memory reset */
  if (QSPI_ResetMemory(&hqspi) != QSPI_OK)
  {
    Error_Handler();
  }

  /* Set the QSPI memory in 4-bytes address mode */
  if (QSPI_EnterFourBytesAddress(&hqspi) != QSPI_OK)
  {
    Error_Handler();
  }

  /* Configuration of the dummy cycles on QSPI memory side */
  if (QSPI_DummyCyclesCfg(&hqspi) != QSPI_OK)
  {
    Error_Handler();
  }

  QSPI_EnableMemoryMappedMode();
  /* USER CODE END QUADSPI_Init 2 */

}

/* FMC initialization function */
static void MX_FMC_Init(void)
{

  FMC_SDRAM_TimingTypeDef SdramTiming = {0};

  /** Perform the SDRAM1 memory initialization sequence
  */
  hsdram1.Instance = FMC_SDRAM_DEVICE;
  /* hsdram1.Init */
  hsdram1.Init.SDBank = FMC_SDRAM_BANK1;
  hsdram1.Init.ColumnBitsNumber = FMC_SDRAM_COLUMN_BITS_NUM_9;
  hsdram1.Init.RowBitsNumber = FMC_SDRAM_ROW_BITS_NUM_12;
  hsdram1.Init.MemoryDataWidth = FMC_SDRAM_MEM_BUS_WIDTH_32;
  hsdram1.Init.InternalBankNumber = FMC_SDRAM_INTERN_BANKS_NUM_4;
  hsdram1.Init.CASLatency = FMC_SDRAM_CAS_LATENCY_3;
  hsdram1.Init.WriteProtection = FMC_SDRAM_WRITE_PROTECTION_DISABLE;
  hsdram1.Init.SDClockPeriod = FMC_SDRAM_CLOCK_PERIOD_2;
  hsdram1.Init.ReadBurst = FMC_SDRAM_RBURST_ENABLE;
  hsdram1.Init.ReadPipeDelay = FMC_SDRAM_RPIPE_DELAY_0;
  /* SdramTiming */
  SdramTiming.LoadToActiveDelay = 2;
  SdramTiming.ExitSelfRefreshDelay = 7;
  SdramTiming.SelfRefreshTime = 4;
  SdramTiming.RowCycleDelay = 7;
  SdramTiming.WriteRecoveryTime = 3;
  SdramTiming.RPDelay = 2;
  SdramTiming.RCDDelay = 2;

  if (HAL_SDRAM_Init(&hsdram1, &SdramTiming) != HAL_OK)
  {
    Error_Handler( );
  }

  /* USER CODE BEGIN FMC_Init 2 */

  /* SDRAM initialization sequence */
  BSP_SDRAM_Initialization_sequence(REFRESH_COUNT);

  //Deactivate speculative/cache access to first FMC Bank to save FMC bandwidth
    FMC_Bank1->BTCR[0] = 0x000030D2;
  /* USER CODE END FMC_Init 2 */
}

static void MX_GPIO_Init(void)
{
  GPIO_InitTypeDef GPIO_InitStruct = {0};

  /* GPIO Ports Clock Enable */
  __HAL_RCC_GPIOE_CLK_ENABLE();
  __HAL_RCC_GPIOB_CLK_ENABLE();
  __HAL_RCC_GPIOA_CLK_ENABLE();
  __HAL_RCC_GPIOG_CLK_ENABLE();
  __HAL_RCC_GPIOJ_CLK_ENABLE();
  __HAL_RCC_GPIOD_CLK_ENABLE();
  __HAL_RCC_GPIOI_CLK_ENABLE();
  __HAL_RCC_GPIOK_CLK_ENABLE();
  __HAL_RCC_GPIOF_CLK_ENABLE();
  __HAL_RCC_GPIOH_CLK_ENABLE();
  __HAL_RCC_GPIOC_CLK_ENABLE();

  /*Configure GPIO pin Output Level */
  HAL_GPIO_WritePin(GPIOC, RENDER_TIME_Pin|MCU_ACTIVE_Pin, GPIO_PIN_RESET);

  /*Configure GPIO pin Output Level */
  HAL_GPIO_WritePin(GPIOA, VSYNC_FREQ_Pin|FRAME_RATE_Pin, GPIO_PIN_RESET);

  /*Configure GPIO pins : RENDER_TIME_Pin MCU_ACTIVE_Pin */
  GPIO_InitStruct.Pin = RENDER_TIME_Pin|MCU_ACTIVE_Pin;
  GPIO_InitStruct.Mode = GPIO_MODE_OUTPUT_PP;
  GPIO_InitStruct.Pull = GPIO_NOPULL;
  GPIO_InitStruct.Speed = GPIO_SPEED_FREQ_VERY_HIGH;
  HAL_GPIO_Init(GPIOC, &GPIO_InitStruct);

  /*Configure GPIO pins : VSYNC_FREQ_Pin FRAME_RATE_Pin */
  GPIO_InitStruct.Pin = VSYNC_FREQ_Pin|FRAME_RATE_Pin;
  GPIO_InitStruct.Mode = GPIO_MODE_OUTPUT_PP;
  GPIO_InitStruct.Pull = GPIO_NOPULL;
  GPIO_InitStruct.Speed = GPIO_SPEED_FREQ_VERY_HIGH;
  HAL_GPIO_Init(GPIOA, &GPIO_InitStruct);

}

/* USER CODE BEGIN 4 */
/**
  * @brief  Configure the QSPI in memory-mapped mode
  * @retval QSPI memory status
  */
static uint8_t QSPI_EnableMemoryMappedMode(void)
{
  QSPI_CommandTypeDef      s_command;
  QSPI_MemoryMappedTypeDef s_mem_mapped_cfg;

  /* Configure the command for the read instruction */
  s_command.InstructionMode   = QSPI_INSTRUCTION_1_LINE;
  s_command.Instruction       = QUAD_OUT_FAST_READ_CMD;
  s_command.AddressMode       = QSPI_ADDRESS_1_LINE;
  s_command.AddressSize       = QSPI_ADDRESS_32_BITS;
  s_command.AlternateByteMode = QSPI_ALTERNATE_BYTES_NONE;
  s_command.DataMode          = QSPI_DATA_4_LINES;
  s_command.DummyCycles       = N25Q512A_DUMMY_CYCLES_READ_QUAD;
  s_command.DdrMode           = QSPI_DDR_MODE_DISABLE;
  s_command.DdrHoldHalfCycle  = QSPI_DDR_HHC_ANALOG_DELAY;
  s_command.SIOOMode          = QSPI_SIOO_INST_EVERY_CMD;

  /* Configure the memory mapped mode */
  s_mem_mapped_cfg.TimeOutActivation = QSPI_TIMEOUT_COUNTER_DISABLE;
  s_mem_mapped_cfg.TimeOutPeriod     = 0;

  if (HAL_QSPI_MemoryMapped(&hqspi, &s_command, &s_mem_mapped_cfg) != HAL_OK)
  {
    return QSPI_ERROR;
  }

  return QSPI_OK;
}

/**
  * @brief  This function reset the QSPI memory.
  * @param  hqspi: QSPI handle
  * @retval None
  */
static uint8_t QSPI_ResetMemory(QSPI_HandleTypeDef *hqspi)
{
  QSPI_CommandTypeDef s_command;

  /* Initialize the reset enable command */
  s_command.InstructionMode   = QSPI_INSTRUCTION_1_LINE;
  s_command.Instruction       = RESET_ENABLE_CMD;
  s_command.AddressMode       = QSPI_ADDRESS_NONE;
  s_command.AlternateByteMode = QSPI_ALTERNATE_BYTES_NONE;
  s_command.DataMode          = QSPI_DATA_NONE;
  s_command.DummyCycles       = 0;
  s_command.DdrMode           = QSPI_DDR_MODE_DISABLE;
  s_command.DdrHoldHalfCycle  = QSPI_DDR_HHC_ANALOG_DELAY;
  s_command.SIOOMode          = QSPI_SIOO_INST_EVERY_CMD;

  /* Send the command */
  if (HAL_QSPI_Command(hqspi, &s_command, HAL_QPSI_TIMEOUT_DEFAULT_VALUE) != HAL_OK)
  {
    return QSPI_ERROR;
  }

  /* Send the reset memory command */
  s_command.Instruction = RESET_MEMORY_CMD;
  if (HAL_QSPI_Command(hqspi, &s_command, HAL_QPSI_TIMEOUT_DEFAULT_VALUE) != HAL_OK)
  {
    return QSPI_ERROR;
  }

  /* Configure automatic polling mode to wait the memory is ready */
  if (QSPI_AutoPollingMemReady(hqspi, HAL_QPSI_TIMEOUT_DEFAULT_VALUE) != QSPI_OK)
  {
    return QSPI_ERROR;
  }

  return QSPI_OK;
}

/**
  * @brief  This function set the QSPI memory in 4-byte address mode
  * @param  hqspi: QSPI handle
  * @retval None
  */
static uint8_t QSPI_EnterFourBytesAddress(QSPI_HandleTypeDef *hqspi)
{
  QSPI_CommandTypeDef s_command;

  /* Initialize the command */
  s_command.InstructionMode   = QSPI_INSTRUCTION_1_LINE;
  s_command.Instruction       = ENTER_4_BYTE_ADDR_MODE_CMD;
  s_command.AddressMode       = QSPI_ADDRESS_NONE;
  s_command.AlternateByteMode = QSPI_ALTERNATE_BYTES_NONE;
  s_command.DataMode          = QSPI_DATA_NONE;
  s_command.DummyCycles       = 0;
  s_command.DdrMode           = QSPI_DDR_MODE_DISABLE;
  s_command.DdrHoldHalfCycle  = QSPI_DDR_HHC_ANALOG_DELAY;
  s_command.SIOOMode          = QSPI_SIOO_INST_EVERY_CMD;

  /* Enable write operations */
  if (QSPI_WriteEnable(hqspi) != QSPI_OK)
  {
    return QSPI_ERROR;
  }

  /* Send the command */
  if (HAL_QSPI_Command(hqspi, &s_command, HAL_QPSI_TIMEOUT_DEFAULT_VALUE) != HAL_OK)
  {
    return QSPI_ERROR;
  }

  /* Configure automatic polling mode to wait the memory is ready */
  if (QSPI_AutoPollingMemReady(hqspi, HAL_QPSI_TIMEOUT_DEFAULT_VALUE) != QSPI_OK)
  {
    return QSPI_ERROR;
  }

  return QSPI_OK;
}

/**
  * @brief  This function configure the dummy cycles on memory side.
  * @param  hqspi: QSPI handle
  * @retval None
  */
static uint8_t QSPI_DummyCyclesCfg(QSPI_HandleTypeDef *hqspi)
{
  QSPI_CommandTypeDef s_command;
  uint8_t reg;

  /* Initialize the read volatile configuration register command */
  s_command.InstructionMode   = QSPI_INSTRUCTION_1_LINE;
  s_command.Instruction       = READ_VOL_CFG_REG_CMD;
  s_command.AddressMode       = QSPI_ADDRESS_NONE;
  s_command.AlternateByteMode = QSPI_ALTERNATE_BYTES_NONE;
  s_command.DataMode          = QSPI_DATA_1_LINE;
  s_command.DummyCycles       = 0;
  s_command.NbData            = 1;
  s_command.DdrMode           = QSPI_DDR_MODE_DISABLE;
  s_command.DdrHoldHalfCycle  = QSPI_DDR_HHC_ANALOG_DELAY;
  s_command.SIOOMode          = QSPI_SIOO_INST_EVERY_CMD;

  /* Configure the command */
  if (HAL_QSPI_Command(hqspi, &s_command, HAL_QPSI_TIMEOUT_DEFAULT_VALUE) != HAL_OK)
  {
    return QSPI_ERROR;
  }

  /* Reception of the data */
  if (HAL_QSPI_Receive(hqspi, &reg, HAL_QPSI_TIMEOUT_DEFAULT_VALUE) != HAL_OK)
  {
    return QSPI_ERROR;
  }

  /* Enable write operations */
  if (QSPI_WriteEnable(hqspi) != QSPI_OK)
  {
    return QSPI_ERROR;
  }

  /* Update volatile configuration register (with new dummy cycles) */
  s_command.Instruction = WRITE_VOL_CFG_REG_CMD;
  MODIFY_REG(reg, N25Q512A_VCR_NB_DUMMY, (N25Q512A_DUMMY_CYCLES_READ_QUAD << POSITION_VAL(N25Q512A_VCR_NB_DUMMY)));

  /* Configure the write volatile configuration register command */
  if (HAL_QSPI_Command(hqspi, &s_command, HAL_QPSI_TIMEOUT_DEFAULT_VALUE) != HAL_OK)
  {
    return QSPI_ERROR;
  }

  /* Transmission of the data */
  if (HAL_QSPI_Transmit(hqspi, &reg, HAL_QPSI_TIMEOUT_DEFAULT_VALUE) != HAL_OK)
  {
    return QSPI_ERROR;
  }

  return QSPI_OK;
}

/**
  * @brief  This function send a Write Enable and wait it is effective.
  * @param  hqspi: QSPI handle
  * @retval None
  */
static uint8_t QSPI_WriteEnable(QSPI_HandleTypeDef *hqspi)
{
  QSPI_CommandTypeDef     s_command;
  QSPI_AutoPollingTypeDef s_config;

  /* Enable write operations */
  s_command.InstructionMode   = QSPI_INSTRUCTION_1_LINE;
  s_command.Instruction       = WRITE_ENABLE_CMD;
  s_command.AddressMode       = QSPI_ADDRESS_NONE;
  s_command.AlternateByteMode = QSPI_ALTERNATE_BYTES_NONE;
  s_command.DataMode          = QSPI_DATA_NONE;
  s_command.DummyCycles       = 0;
  s_command.DdrMode           = QSPI_DDR_MODE_DISABLE;
  s_command.DdrHoldHalfCycle  = QSPI_DDR_HHC_ANALOG_DELAY;
  s_command.SIOOMode          = QSPI_SIOO_INST_EVERY_CMD;

  if (HAL_QSPI_Command(hqspi, &s_command, HAL_QPSI_TIMEOUT_DEFAULT_VALUE) != HAL_OK)
  {
    return QSPI_ERROR;
  }

  /* Configure automatic polling mode to wait for write enabling */
  s_config.Match           = N25Q512A_SR_WREN;
  s_config.Mask            = N25Q512A_SR_WREN;
  s_config.MatchMode       = QSPI_MATCH_MODE_AND;
  s_config.StatusBytesSize = 1;
  s_config.Interval        = 0x10;
  s_config.AutomaticStop   = QSPI_AUTOMATIC_STOP_ENABLE;

  s_command.Instruction    = READ_STATUS_REG_CMD;
  s_command.DataMode       = QSPI_DATA_1_LINE;

  if (HAL_QSPI_AutoPolling(hqspi, &s_command, &s_config, HAL_QPSI_TIMEOUT_DEFAULT_VALUE) != HAL_OK)
  {
    return QSPI_ERROR;
  }

  return QSPI_OK;
}

/**
  * @brief  This function read the SR of the memory and wait the EOP.
  * @param  hqspi: QSPI handle
  * @retval None
  */
static uint8_t QSPI_AutoPollingMemReady(QSPI_HandleTypeDef *hqspi, uint32_t Timeout)
{
  QSPI_CommandTypeDef     s_command;
  QSPI_AutoPollingTypeDef s_config;

  /* Configure automatic polling mode to wait for memory ready */
  s_command.InstructionMode   = QSPI_INSTRUCTION_1_LINE;
  s_command.Instruction       = READ_STATUS_REG_CMD;
  s_command.AddressMode       = QSPI_ADDRESS_NONE;
  s_command.AlternateByteMode = QSPI_ALTERNATE_BYTES_NONE;
  s_command.DataMode          = QSPI_DATA_1_LINE;
  s_command.DummyCycles       = 0;
  s_command.DdrMode           = QSPI_DDR_MODE_DISABLE;
  s_command.DdrHoldHalfCycle  = QSPI_DDR_HHC_ANALOG_DELAY;
  s_command.SIOOMode          = QSPI_SIOO_INST_EVERY_CMD;

  s_config.Match           = 0;
  s_config.Mask            = N25Q512A_SR_WIP;
  s_config.MatchMode       = QSPI_MATCH_MODE_AND;
  s_config.StatusBytesSize = 1;
  s_config.Interval        = 0x10;
  s_config.AutomaticStop   = QSPI_AUTOMATIC_STOP_ENABLE;

  if (HAL_QSPI_AutoPolling(hqspi, &s_command, &s_config, Timeout) != HAL_OK)
  {
    return QSPI_ERROR;
  }

  return QSPI_OK;
}

/**
  * @brief  Programs the SDRAM device.
  * @param  RefreshCount: SDRAM refresh counter value
  * @retval None
  */
void BSP_SDRAM_Initialization_sequence(uint32_t RefreshCount)
{
  __IO uint32_t tmpmrd = 0;

  /* Step 1: Configure a clock configuration enable command */
  Command.CommandMode            = FMC_SDRAM_CMD_CLK_ENABLE;
  Command.CommandTarget          = FMC_SDRAM_CMD_TARGET_BANK1;
  Command.AutoRefreshNumber      = 1;
  Command.ModeRegisterDefinition = 0;

  /* Send the command */
  HAL_SDRAM_SendCommand(&hsdram1, &Command, SDRAM_TIMEOUT);

  /* Step 2: Insert 100 us minimum delay */
  /* Inserted delay is equal to 1 ms due to systick time base unit (ms) */
  HAL_Delay(1);

  /* Step 3: Configure a PALL (precharge all) command */
  Command.CommandMode            = FMC_SDRAM_CMD_PALL;
  Command.CommandTarget          = FMC_SDRAM_CMD_TARGET_BANK1;
  Command.AutoRefreshNumber      = 1;
  Command.ModeRegisterDefinition = 0;

  /* Send the command */
  HAL_SDRAM_SendCommand(&hsdram1, &Command, SDRAM_TIMEOUT);

  /* Step 4: Configure an Auto Refresh command */
  Command.CommandMode            = FMC_SDRAM_CMD_AUTOREFRESH_MODE;
  Command.CommandTarget          = FMC_SDRAM_CMD_TARGET_BANK1;
  Command.AutoRefreshNumber      = 8;
  Command.ModeRegisterDefinition = 0;

  /* Send the command */
  HAL_SDRAM_SendCommand(&hsdram1, &Command, SDRAM_TIMEOUT);

  /* Step 5: Program the external memory mode register */
  tmpmrd = (uint32_t)SDRAM_MODEREG_BURST_LENGTH_1          |\
                     SDRAM_MODEREG_BURST_TYPE_SEQUENTIAL   |\
                     SDRAM_MODEREG_CAS_LATENCY_3           |\
                     SDRAM_MODEREG_OPERATING_MODE_STANDARD |\
                     SDRAM_MODEREG_WRITEBURST_MODE_SINGLE;

  Command.CommandMode            = FMC_SDRAM_CMD_LOAD_MODE;
  Command.CommandTarget          = FMC_SDRAM_CMD_TARGET_BANK1;
  Command.AutoRefreshNumber      = 1;
  Command.ModeRegisterDefinition = tmpmrd;

  /* Send the command */
  HAL_SDRAM_SendCommand(&hsdram1, &Command, SDRAM_TIMEOUT);

  /* Step 6: Set the refresh rate counter */
  /* Set the device refresh rate */
  HAL_SDRAM_ProgramRefreshRate(&hsdram1, RefreshCount);
}

/* USER CODE END 4 */

void StartDefaultTask(void *argument)
{
  /* USER CODE BEGIN 5 */
  /* Infinite loop */
  for(;;)
  {
    osDelay(100);
  }
  /* USER CODE END 5 */
}

/* MPU Configuration */

void MPU_Config(void)
{
  MPU_Region_InitTypeDef MPU_InitStruct = {0};

  /* Disables the MPU */
  HAL_MPU_Disable();

  /** Initializes and configures the Region and the memory to be protected
  */
  MPU_InitStruct.Enable = MPU_REGION_ENABLE;
  MPU_InitStruct.Number = MPU_REGION_NUMBER0;
  MPU_InitStruct.BaseAddress = 0xC0000000;
  MPU_InitStruct.Size = MPU_REGION_SIZE_512MB;
  MPU_InitStruct.SubRegionDisable = 0x0;
  MPU_InitStruct.TypeExtField = MPU_TEX_LEVEL0;
  MPU_InitStruct.AccessPermission = MPU_REGION_NO_ACCESS;
  MPU_InitStruct.DisableExec = MPU_INSTRUCTION_ACCESS_DISABLE;
  MPU_InitStruct.IsShareable = MPU_ACCESS_NOT_SHAREABLE;
  MPU_InitStruct.IsCacheable = MPU_ACCESS_NOT_CACHEABLE;
  MPU_InitStruct.IsBufferable = MPU_ACCESS_NOT_BUFFERABLE;

  HAL_MPU_ConfigRegion(&MPU_InitStruct);

  /** Initializes and configures the Region and the memory to be protected
  */
  MPU_InitStruct.Number = MPU_REGION_NUMBER1;
  MPU_InitStruct.Size = MPU_REGION_SIZE_8MB;
  MPU_InitStruct.AccessPermission = MPU_REGION_FULL_ACCESS;
  MPU_InitStruct.IsCacheable = MPU_ACCESS_CACHEABLE;
  MPU_InitStruct.IsBufferable = MPU_ACCESS_BUFFERABLE;

  HAL_MPU_ConfigRegion(&MPU_InitStruct);

  /** Initializes and configures the Region and the memory to be protected
  */
  MPU_InitStruct.Number = MPU_REGION_NUMBER2;
  MPU_InitStruct.BaseAddress = 0x90000000;
  MPU_InitStruct.Size = MPU_REGION_SIZE_512MB;
  MPU_InitStruct.SubRegionDisable = 0x00;
  MPU_InitStruct.AccessPermission = MPU_REGION_NO_ACCESS;
  MPU_InitStruct.IsCacheable = MPU_ACCESS_NOT_CACHEABLE;
  MPU_InitStruct.IsBufferable = MPU_ACCESS_NOT_BUFFERABLE;

  HAL_MPU_ConfigRegion(&MPU_InitStruct);

  /** Initializes and configures the Region and the memory to be protected
  */
  MPU_InitStruct.Number = MPU_REGION_NUMBER3;
  MPU_InitStruct.Size = MPU_REGION_SIZE_64MB;
  MPU_InitStruct.SubRegionDisable = 0x0;
  MPU_InitStruct.AccessPermission = MPU_REGION_FULL_ACCESS;
  MPU_InitStruct.IsCacheable = MPU_ACCESS_CACHEABLE;
  MPU_InitStruct.IsBufferable = MPU_ACCESS_BUFFERABLE;

  HAL_MPU_ConfigRegion(&MPU_InitStruct);
  /* Enables the MPU */
  HAL_MPU_Enable(MPU_PRIVILEGED_DEFAULT);

}

void HAL_TIM_PeriodElapsedCallback(TIM_HandleTypeDef *htim)
{
  if (htim->Instance == TIM6) {
    HAL_IncTick();
  }
}

void Error_Handler(void)
{
}

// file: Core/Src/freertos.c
/* USER CODE BEGIN Header */
/**
  ******************************************************************************
  * File Name          : freertos.c
  * Description        : Code for freertos applications
  ******************************************************************************
  * @attention
  *
  * <h2><center>&copy; Copyright (c) 2020 STMicroelectronics.
  * All rights reserved.</center></h2>
  *
  * This software component is licensed by ST under Ultimate Liberty license
  * SLA0044, the "License"; You may not use this file except in compliance with
  * the License. You may obtain a copy of the License at:
  *                             www.st.com/SLA0044
  *
  ******************************************************************************
  */
/* USER CODE END Header */

#include "FreeRTOS.h"
#include "task.h"
#include "main.h"

/* USER CODE BEGIN FunctionPrototypes */
extern portBASE_TYPE IdleTaskHook(void* p);
/* USER CODE END FunctionPrototypes */

/* Hook prototypes */
void vApplicationIdleHook(void);

/* USER CODE BEGIN 2 */
void vApplicationIdleHook( void )
{
   /* vApplicationIdleHook() will only be called if configUSE_IDLE_HOOK is set
   to 1 in FreeRTOSConfig.h. It will be called on each iteration of the idle
   task. It is essential that code added to this hook function never attempts
   to block in any way (for example, call xQueueReceive() with a block time
   specified, or call vTaskDelay()). If the application makes use of the
   vTaskDelete() API function (as this demo application does) then it is also
   important that vApplicationIdleHook() is permitted to return to its calling
   function, because it is the responsibility of the idle task to clean up
   memory allocated by the kernel to any task that has since been deleted. */
	vTaskSetApplicationTaskTag(NULL, IdleTaskHook);
}
/* USER CODE END 2 */
